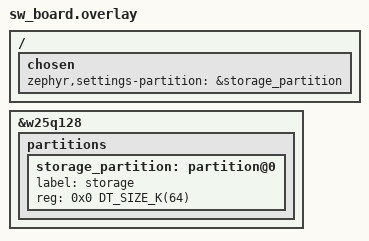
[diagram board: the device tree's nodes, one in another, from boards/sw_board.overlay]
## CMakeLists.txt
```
cmake_minimum_required(VERSION 3.20.0)

set(FSW_ROOT ${CMAKE_CURRENT_SOURCE_DIR}/../../..)

find_package(Zephyr REQUIRED HINTS $ENV{ZEPHYR_BASE})
project(storage LANGUAGES CXX)

target_compile_options(app PRIVATE -Wall -Wextra -Wno-unused-parameter -Wno-unused-function -Wno-ignored-qualifiers)
FILE(GLOB app_sources src/*.cpp)
target_sources(app PRIVATE ${app_sources})
```

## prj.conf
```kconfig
CONFIG_CPP=y
CONFIG_REQUIRES_FULL_LIBCPP=y
CONFIG_STD_CPP20=y


CONFIG_F_CORE=y
CONFIG_F_CORE_OS=y

CONFIG_FLASH=y
CONFIG_FLASH_MAP=y
CONFIG_FLASH_PAGE_LAYOUT=y
CONFIG_SETTINGS_NVS=y
CONFIG_NVS=y

CONFIG_SETTINGS=y
CONFIG_REBOOT=y

# Outputs
CONFIG_SERIAL=y
CONFIG_STDOUT_CONSOLE=y
CONFIG_FILE_SYSTEM_SHELL=y
CONFIG_HEAP_MEM_POOL_SIZE=8192

CONFIG_DEBUG=y
CONFIG_CBPRINTF_FP_SUPPORT=y
CONFIG_LOG=y
CONFIG_LOG_MODE_DEFERRED=y
CONFIG_LOG_BUFFER_SIZE=16384
CONFIG_LOG_PROCESS_THREAD_STARTUP_DELAY_MS=200
CONFIG_UART_LINE_CTRL=y

CONFIG_USBD_LOG_LEVEL_WRN=y
CONFIG_UDC_DRIVER_LOG_LEVEL_WRN=y
CONFIG_USBD_CDC_ACM_LOG_LEVEL_WRN=y

CONFIG_MAIN_STACK_SIZE=4096
```

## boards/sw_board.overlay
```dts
&w25q128 {
  partitions {
    storage_partition: partition@0 {
      label = "storage";
      reg = <0x0 DT_SIZE_K(64)>;
    };
  };
};

/ {
  chosen {
    zephyr,settings-partition = &storage_partition;
  };
};
    
```

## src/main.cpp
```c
#include <stdio.h>
#include <zephyr/kernel.h>
#include <zephyr/logging/log.h>
#include <zephyr/sys/reboot.h>
#include <zephyr/settings/settings.h>

LOG_MODULE_REGISTER(main);

#define DEFAULT_VAL 0

static uint8_t storedVal = DEFAULT_VAL;

// read test setting from flash
static int test_settings_set(const char *name, size_t len, settings_read_cb read_cb, void *cb_arg) {
    const char *next;
    int rc;

    LOG_INF("name is %s, len %d", name, len);

    if (settings_name_steq(name, "test_child", &next) && !next) {
        // if the read storage doesn't match, be sad
        if (len != sizeof(storedVal)) {
            return -EINVAL;
        }

        rc = read_cb(cb_arg, &storedVal, sizeof(storedVal));

        if (rc >= 0) {
            // rc contains value length, so it'll
            // be 0 if key-value is properly read
            return 0;
        }

        return rc;
    }

    return -ENOENT;
}

static int test_settings_export(int (*storage_func)(const char *name, const void *value, size_t val_len)) {
    return storage_func("test/test_child", &storedVal, sizeof(storedVal));
}

struct settings_handler config = {.name = "test", .h_set = test_settings_set, .h_export = test_settings_export};

int main() {
    k_msleep(1000);

    int rc1 = settings_subsys_init();
    int rc2 = settings_register(&config);
    int rc3 = settings_load();

    for (int i = 0; 1; i++) {
      storedVal++;
      int rc4 = settings_save_one("test/test_child", &storedVal, sizeof(storedVal));

      LOG_INF("HI, value is %d", storedVal);
      LOG_INF("RC1 = %d", rc1);
      LOG_INF("RC2 = %d", rc2);
      LOG_INF("RC3 = %d", rc3);
      LOG_INF("RC4 = %d", rc4);

      k_msleep(1000);
    }

    LOG_INF("Rebooting!");

    k_msleep(1000);

    sys_reboot(SYS_REBOOT_COLD);

    return 0;
}
```
